# va416xx register map
Vendor: VORAGO TECHNOLOGIES; Series: M4; File version: 1.3
CPU: CM4 r0p1, little endian, no MPU, FPU, 4 interrupt priority bits
Registers are 32-bit, read-write, reset 0x0 unless marked. A register's access mark holds for its fields unless they carry their own. Offsets are from the block's base; [hi:lo] are bit positions; {n}, {i} and the like mark numbered series; 'fields as' and 'values as' point back to an identical list.

## CAN0 — CAN Peripheral
Base 0x40014000
Same registers: CAN1 0x40014400
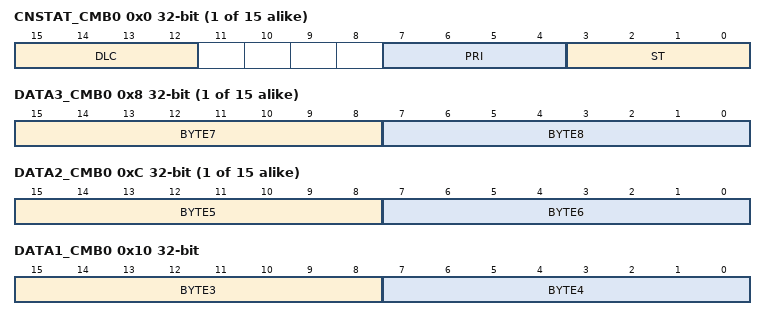
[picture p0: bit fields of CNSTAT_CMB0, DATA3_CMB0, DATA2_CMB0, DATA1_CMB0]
{0x0+0x20*i} CNSTAT_CMB{i} (i=0..14) — Buffer Status / Control Register
  [15:12] DLC — Data Length Code
  [7:4] PRI — Transmit Priority Code
  [3:0] ST — Buffer Status
{0x4+0x20*i} TSTP_CMB{i} (i=0..14) — CAN Frame Timestamp
  [15:0] TIMESTAMP
{0x8+0x20*i} DATA3_CMB{i} (i=0..14) — CAN Frame Data Word 3
  [15:8] BYTE7 — Data Byte 7
  [7:0] BYTE8 — Data Byte 8
{0xC+0x20*i} DATA2_CMB{i} (i=0..14) — CAN Frame Data Word 2
  [15:8] BYTE5 — Data Byte 5
  [7:0] BYTE6 — Data Byte 6
0x10 DATA1_CMB0 — CAN Frame Data Word 1
  [15:8] BYTE3 — Data Byte 3
  [7:0] BYTE4 — Data Byte 4
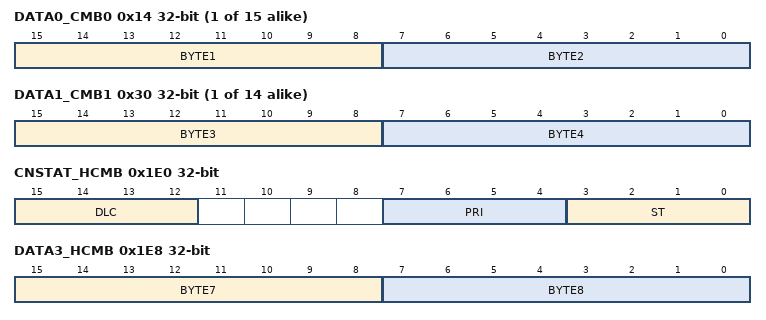
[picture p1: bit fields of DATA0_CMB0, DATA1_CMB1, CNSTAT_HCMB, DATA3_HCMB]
{0x14+0x20*i} DATA0_CMB{i} (i=0..14) — CAN Frame Data Word 0
  [15:8] BYTE1 — Data Byte 1
  [7:0] BYTE2 — Data Byte 2
{0x18+0x20*i} ID0_CMB{i} (i=0..14) — CAN Frame Identifier Word 0
  [15:0] ID0 — Half of CAN Frame ID. Format Varies for Standard or Extended Frames
{0x1C+0x20*i} ID1_CMB{i} (i=0..14) — CAN Frame Identifier Word 1
  [15:0] ID1 — Half of CAN Frame ID. Format Varies for Standard or Extended Frames
{0x10+0x20*i} DATA1_CMB{i} (i=1..14) — CAN Frame Data Word 2
  [15:8] BYTE3 — Data Byte 3
  [7:0] BYTE4 — Data Byte 4
0x1E0 CNSTAT_HCMB — Buffer Status / Control Register
  fields as CNSTAT_CMB0
0x1E4 TSTP_HCMB — CAN Frame Timestamp
  [15:0] TIMESTAMP
0x1E8 DATA3_HCMB — CAN Frame Data Word 3
  [15:8] BYTE7 — Data Byte 7
  [7:0] BYTE8 — Data Byte 8
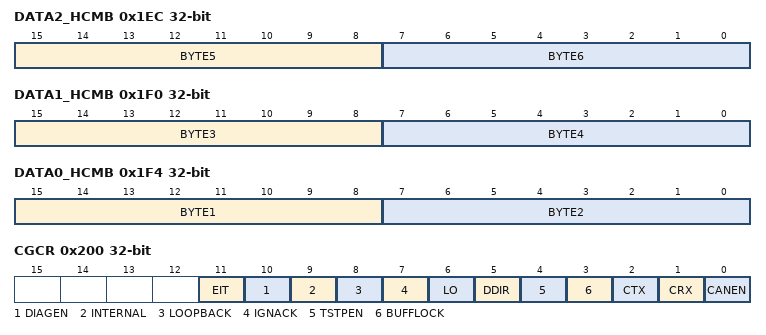
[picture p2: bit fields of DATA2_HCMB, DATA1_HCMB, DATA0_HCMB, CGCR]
0x1EC DATA2_HCMB — CAN Frame Data Word 2
  [15:8] BYTE5 — Data Byte 5
  [7:0] BYTE6 — Data Byte 6
0x1F0 DATA1_HCMB — CAN Frame Data Word 2
  [15:8] BYTE3 — Data Byte 3
  [7:0] BYTE4 — Data Byte 4
0x1F4 DATA0_HCMB — CAN Frame Data Word 0
  [15:8] BYTE1 — Data Byte 1
  [7:0] BYTE2 — Data Byte 2
0x1F8 ID0_HCMB — CAN Frame Identifier Word 0
  fields as ID0_CMB0
0x1FC ID1_HCMB — CAN Frame Identifier Word 1
  fields as ID1_CMB0
0x200 CGCR — CAN Global Configuration Register
  [11] EIT — Error Interrupt Type
  [10] DIAGEN — Diagnostic Enable
  [9] INTERNAL
  [8] LOOPBACK
  [7] IGNACK — Ignore Acknowledge
  [6] LO — Listen Only
  [5] DDIR — Data Direction
  [4] TSTPEN — Time Sync Enable
  [3] BUFFLOCK — Buffer Lock
  [2] CTX — RW,Control Transmit
  [1] CRX — RW,Control Receive
  [0] CANEN — CAN Enable
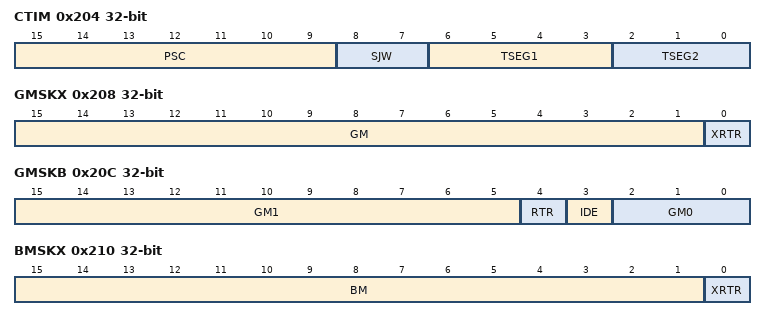
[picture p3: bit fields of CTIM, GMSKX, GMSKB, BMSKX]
0x204 CTIM — CAN Timing Register
  [15:9] PSC — Prescaler Configuration
  [8:7] SJW — Synchronization Jump Width
  [6:3] TSEG1 — Time Segment 1
  [2:0] TSEG2 — Time Segment 2
0x208 GMSKX — CAN Global Mask Extension
  [15:1] GM — GM[14:0] used when an extended frame is received. ID[14:0] in extended, unused standard
  [0] XRTR — Extended Remote transmission Request Bit
0x20C GMSKB — CAN Global Mask Base
  [15:5] GM1 — GM[28:18] - ID[10:0] in standard, ID[28:18] in extended
  [4] RTR — Remote Transmission Request in Standard, Substitute Remote Request (SRR) in extended
  [3] IDE — Identifier Extension Bit
  [2:0] GM0 — GM[17:15] - Unused in standard, ID[17:15] in extended
0x210 BMSKX — CAN Basic Mask Extension
  [15:1] BM — BM[14:0] used when an extended frame is received. ID[14:0] in extended, unused standard
  [0] XRTR — Extended Remote transmission Request Bit
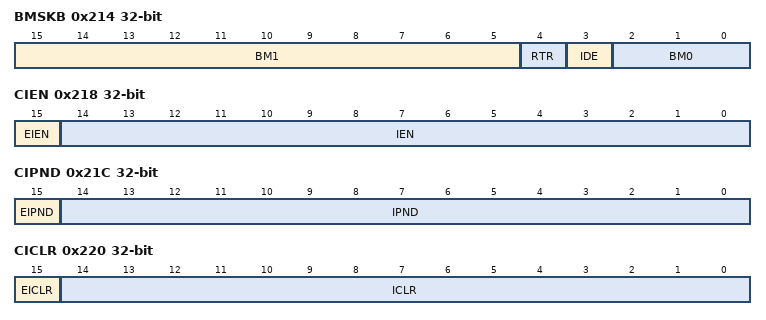
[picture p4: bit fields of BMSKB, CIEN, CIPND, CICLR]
0x214 BMSKB — CAN Basic Mask Base
  [15:5] BM1 — BM[28:18] - ID[10:0] in standard, ID[28:18] in extended
  [4] RTR — Remote Transmission Request in Standard, Substitute Remote Request (SRR) in extended
  [3] IDE — Identifier Extension Bit
  [2:0] BM0 — BM[17:15] - Unused in standard, ID[17:15] in extended
0x218 CIEN — CAN Interrupt Enable Register
  [15] EIEN — Error Interrupt Enable
  [14:0] IEN — Buffer Interrupt Enable[14:0]
0x21C CIPND — CAN Interrupt Pending Register
  [15] EIPND — Error Interrupt Pending
  [14:0] IPND — Buffer Interrupt Pending[14:0]
0x220 CICLR — CAN Interrupt Clear Register
  [15] EICLR — Error Interrupt Clear
  [14:0] ICLR — Buffer Interrupt Clear[14:0]
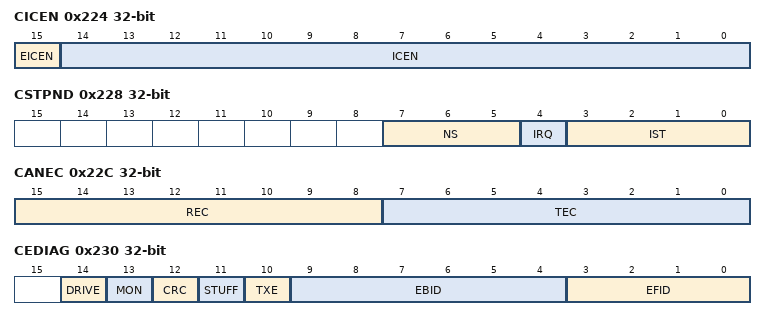
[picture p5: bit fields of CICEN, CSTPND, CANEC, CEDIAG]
0x224 CICEN — CAN Interrupt Code Enable Register
  [15] EICEN — Error Interrupt Code Enable
  [14:0] ICEN — Buffer Interrupt Code Enable[14:0]
0x228 CSTPND — CAN Status Pending Register
  [7:5] NS — CAN Node Status
  [4] IRQ — Interrupt Request portion of Interrupt Code
  [3:0] IST — Interrupt Source portion of Interrupt Code
0x22C CANEC — CAN Error Counter Register
  [15:8] REC — Receive Error Counter
  [7:0] TEC — Transmit Error Counter
0x230 CEDIAG — CAN Error Diagnostic Register
  [14] DRIVE
  [13] MON — Monitor
  [12] CRC
  [11] STUFF — Stuff Error
  [10] TXE — Transmit Error
  [9:4] EBID — Error Bit Identifier
  [3:0] EFID — Error Field Identifier
0x234 CTMR — CAN Timer Register
  [15:0] CTMR ro — Time Stamp Counter
